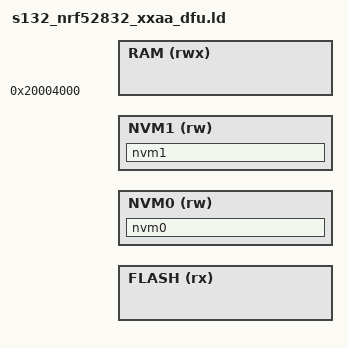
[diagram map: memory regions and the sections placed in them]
/* Application with DFU, nRF52832 xxAA with MBR and S132.
 *
 * Same as nrf52832_xxaa_s132.ld with FLASH cut down to slot 0 and the two
 * NVM regions named, from the layout the stage 0 boot shares. An image that
 * outgrows slot 0 fails to link.
 */

SEARCH_DIR(.)
SEARCH_DIR("../../../../ldscript")
SEARCH_DIR("../../../../../ldscript")
SEARCH_DIR("../../../../../../ldscript")
SEARCH_DIR("../../../../../../../ldscript")
SEARCH_DIR("../../../../IOsonata/ARM/ldscript")
SEARCH_DIR("../../../../../IOsonata/ARM/ldscript")
SEARCH_DIR("../../../../../../IOsonata/ARM/ldscript")
SEARCH_DIR("../../../../../../../IOsonata/ARM/ldscript")
GROUP(-lgcc -lc)

INCLUDE "dfu_layout_nrf52832_s132.ld"

MEMORY
{
	FLASH (rx)	: ORIGIN = __dfu_slot0_start, LENGTH = __dfu_slot0_end - __dfu_slot0_start
	NVM0 (rw)	: ORIGIN = __dfu_nvm0_start, LENGTH = __dfu_nvm_size
	NVM1 (rw)	: ORIGIN = __dfu_nvm1_start, LENGTH = __dfu_nvm_size
	RAM (rwx)	: ORIGIN = 0x20004000, LENGTH = __dfu_flag - 0x20004000
}

SECTIONS
{
	nvm0 (NOLOAD) :
	{
		__start_nvm0 = .;
		KEEP(*(nvm0))
		. = ORIGIN(NVM0) + LENGTH(NVM0);
		__stop_nvm0 = .;
	} > NVM0

	nvm1 (NOLOAD) :
	{
		__start_nvm1 = .;
		KEEP(*(nvm1))
		. = ORIGIN(NVM1) + LENGTH(NVM1);
		__stop_nvm1 = .;
	} > NVM1
}

SECTIONS
{
	.pwr_mgmt_data :
	{
		PROVIDE(__start_pwr_mgmt_data = .);
		KEEP(*(SORT(.pwr_mgmt_data*)))
		PROVIDE(__stop_pwr_mgmt_data = .);
	} > FLASH

	.log_const_data :
	{
		PROVIDE(__start_log_const_data = .);
		KEEP(*(.log_const_data))
		PROVIDE(__stop_log_const_data = .);
	} > FLASH

	.crypto_data :
	{
		PROVIDE(__start_crypto_data = .);
		KEEP(*(SORT(.crypto_data*)))
		PROVIDE(__stop_crypto_data = .);
	} > FLASH

	.cli_command :
	{
		PROVIDE(__start_cli_command = .);
		KEEP(*(.cli_command))
		PROVIDE(__stop_cli_command = .);
	} > FLASH

	.sdh_stack_observers :
	{
		PROVIDE(__start_sdh_stack_observers = .);
		KEEP(*(SORT(.sdh_stack_observers*)))
		PROVIDE(__stop_sdh_stack_observers = .);
	} > FLASH

	.sdh_req_observers :
	{
		PROVIDE(__start_sdh_req_observers = .);
		KEEP(*(SORT(.sdh_req_observers*)))
		PROVIDE(__stop_sdh_req_observers = .);
	} > FLASH

	.sdh_state_observers :
	{
		PROVIDE(__start_sdh_state_observers = .);
		KEEP(*(SORT(.sdh_state_observers*)))
		PROVIDE(__stop_sdh_state_observers = .);
	} > FLASH

	.sdh_ant_observers :
	{
		PROVIDE(__start_sdh_ant_observers = .);
		KEEP(*(SORT(.sdh_ant_observers*)))
		PROVIDE(__stop_sdh_ant_observers = .);
	} > FLASH

	.sdh_ble_observers :
	{
		PROVIDE(__start_sdh_ble_observers = .);
		KEEP(*(SORT(.sdh_ble_observers*)))
		PROVIDE(__stop_sdh_ble_observers = .);
	} > FLASH

	.sdh_soc_observers :
	{
		PROVIDE(__start_sdh_soc_observers = .);
		KEEP(*(SORT(.sdh_soc_observers*)))
		PROVIDE(__stop_sdh_soc_observers = .);
	} > FLASH

	.nrf_queue :
	{
		PROVIDE(__start_nrf_queue = .);
		KEEP(*(.nrf_queue))
		PROVIDE(__stop_nrf_queue = .);
	} > FLASH
} INSERT AFTER .text

SECTIONS
{
	. = ALIGN(4);
	.svc_data :
	{
		PROVIDE(__start_svc_data = .);
		KEEP(*(.svc_data))
		PROVIDE(__stop_svc_data = .);
	} > RAM AT > FLASH

	.fs_data :
	{
		PROVIDE(__start_fs_data = .);
		KEEP(*(.fs_data))
		PROVIDE(__stop_fs_data = .);
	} > RAM AT > FLASH

	.log_dynamic_data :
	{
		PROVIDE(__start_log_dynamic_data = .);
		KEEP(*(.log_dynamic_data))
		PROVIDE(__stop_log_dynamic_data = .);
	} > RAM AT > FLASH

	.cli_sorted_cmd_ptrs :
	{
		PROVIDE(__start_cli_sorted_cmd_ptrs = .);
		KEEP(*(.cli_sorted_cmd_ptrs))
		PROVIDE(__stop_cli_sorted_cmd_ptrs = .);
	} > RAM AT > FLASH
} INSERT AFTER .data;

INCLUDE "gcc_arm_flash.ld"
